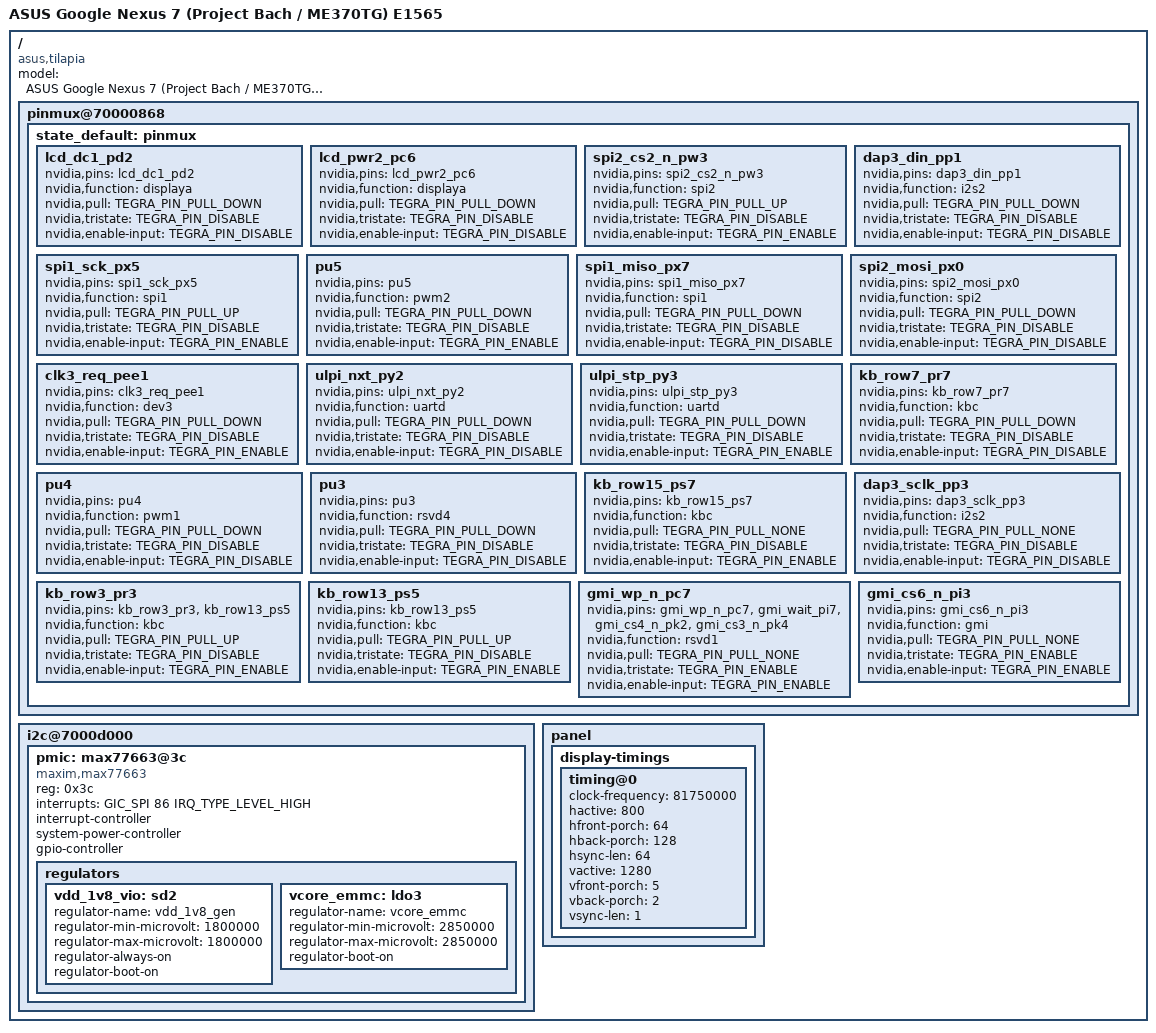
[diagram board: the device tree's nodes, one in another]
// SPDX-License-Identifier: GPL-2.0
/dts-v1/;

#include "tegra30-asus-grouper-common.dtsi"

/ {
	model = "ASUS Google Nexus 7 (Project Bach / ME370TG) E1565";
	compatible = "asus,tilapia", "nvidia,tegra30";

	pinmux@70000868 {
		state_default: pinmux {
			lcd_dc1_pd2 {
				nvidia,pins = "lcd_dc1_pd2";
				nvidia,function = "displaya";
				nvidia,pull = <TEGRA_PIN_PULL_DOWN>;
				nvidia,tristate = <TEGRA_PIN_DISABLE>;
				nvidia,enable-input = <TEGRA_PIN_DISABLE>;
			};
			lcd_pwr2_pc6 {
				nvidia,pins = "lcd_pwr2_pc6";
				nvidia,function = "displaya";
				nvidia,pull = <TEGRA_PIN_PULL_DOWN>;
				nvidia,tristate = <TEGRA_PIN_DISABLE>;
				nvidia,enable-input = <TEGRA_PIN_DISABLE>;
			};
			spi2_cs2_n_pw3 {
				nvidia,pins = "spi2_cs2_n_pw3";
				nvidia,function = "spi2";
				nvidia,pull = <TEGRA_PIN_PULL_UP>;
				nvidia,tristate = <TEGRA_PIN_DISABLE>;
				nvidia,enable-input = <TEGRA_PIN_ENABLE>;
			};
			dap3_din_pp1 {
				nvidia,pins = "dap3_din_pp1";
				nvidia,function = "i2s2";
				nvidia,pull = <TEGRA_PIN_PULL_DOWN>;
				nvidia,tristate = <TEGRA_PIN_DISABLE>;
				nvidia,enable-input = <TEGRA_PIN_DISABLE>;
			};
			spi1_sck_px5 {
				nvidia,pins = "spi1_sck_px5";
				nvidia,function = "spi1";
				nvidia,pull = <TEGRA_PIN_PULL_UP>;
				nvidia,tristate = <TEGRA_PIN_DISABLE>;
				nvidia,enable-input = <TEGRA_PIN_ENABLE>;
			};
			pu5 {
				nvidia,pins = "pu5";
				nvidia,function = "pwm2";
				nvidia,pull = <TEGRA_PIN_PULL_DOWN>;
				nvidia,tristate = <TEGRA_PIN_DISABLE>;
				nvidia,enable-input = <TEGRA_PIN_ENABLE>;
			};
			spi1_miso_px7 {
				nvidia,pins = "spi1_miso_px7";
				nvidia,function = "spi1";
				nvidia,pull = <TEGRA_PIN_PULL_DOWN>;
				nvidia,tristate = <TEGRA_PIN_DISABLE>;
				nvidia,enable-input = <TEGRA_PIN_DISABLE>;
			};
			spi2_mosi_px0 {
				nvidia,pins = "spi2_mosi_px0";
				nvidia,function = "spi2";
				nvidia,pull = <TEGRA_PIN_PULL_DOWN>;
				nvidia,tristate = <TEGRA_PIN_DISABLE>;
				nvidia,enable-input = <TEGRA_PIN_DISABLE>;
			};
			clk3_req_pee1 {
				nvidia,pins = "clk3_req_pee1";
				nvidia,function = "dev3";
				nvidia,pull = <TEGRA_PIN_PULL_DOWN>;
				nvidia,tristate = <TEGRA_PIN_DISABLE>;
				nvidia,enable-input = <TEGRA_PIN_ENABLE>;
			};
			ulpi_nxt_py2 {
				nvidia,pins = "ulpi_nxt_py2";
				nvidia,function = "uartd";
				nvidia,pull = <TEGRA_PIN_PULL_DOWN>;
				nvidia,tristate = <TEGRA_PIN_DISABLE>;
				nvidia,enable-input = <TEGRA_PIN_DISABLE>;
			};
			ulpi_stp_py3 {
				nvidia,pins = "ulpi_stp_py3";
				nvidia,function = "uartd";
				nvidia,pull = <TEGRA_PIN_PULL_DOWN>;
				nvidia,tristate = <TEGRA_PIN_DISABLE>;
				nvidia,enable-input = <TEGRA_PIN_ENABLE>;
			};
			kb_row7_pr7 {
				nvidia,pins = "kb_row7_pr7";
				nvidia,function = "kbc";
				nvidia,pull = <TEGRA_PIN_PULL_DOWN>;
				nvidia,tristate = <TEGRA_PIN_DISABLE>;
				nvidia,enable-input = <TEGRA_PIN_DISABLE>;
			};
			pu4 {
				nvidia,pins = "pu4";
				nvidia,function = "pwm1";
				nvidia,pull = <TEGRA_PIN_PULL_DOWN>;
				nvidia,tristate = <TEGRA_PIN_DISABLE>;
				nvidia,enable-input = <TEGRA_PIN_DISABLE>;
			};
			pu3 {
				nvidia,pins = "pu3";
				nvidia,function = "rsvd4";
				nvidia,pull = <TEGRA_PIN_PULL_DOWN>;
				nvidia,tristate = <TEGRA_PIN_DISABLE>;
				nvidia,enable-input = <TEGRA_PIN_DISABLE>;
			};
			kb_row15_ps7 {
				nvidia,pins = "kb_row15_ps7";
				nvidia,function = "kbc";
				nvidia,pull = <TEGRA_PIN_PULL_NONE>;
				nvidia,tristate = <TEGRA_PIN_DISABLE>;
				nvidia,enable-input = <TEGRA_PIN_ENABLE>;
			};
			dap3_sclk_pp3 {
				nvidia,pins = "dap3_sclk_pp3";
				nvidia,function = "i2s2";
				nvidia,pull = <TEGRA_PIN_PULL_NONE>;
				nvidia,tristate = <TEGRA_PIN_DISABLE>;
				nvidia,enable-input = <TEGRA_PIN_DISABLE>;
			};
			kb_row3_pr3 {
				nvidia,pins = "kb_row3_pr3",
						"kb_row13_ps5";
				nvidia,function = "kbc";
				nvidia,pull = <TEGRA_PIN_PULL_UP>;
				nvidia,tristate = <TEGRA_PIN_DISABLE>;
				nvidia,enable-input = <TEGRA_PIN_ENABLE>;
			};
			kb_row13_ps5 {
				nvidia,pins = "kb_row13_ps5";
				nvidia,function = "kbc";
				nvidia,pull = <TEGRA_PIN_PULL_UP>;
				nvidia,tristate = <TEGRA_PIN_DISABLE>;
				nvidia,enable-input = <TEGRA_PIN_ENABLE>;
			};
			gmi_wp_n_pc7 {
				nvidia,pins = "gmi_wp_n_pc7",
						"gmi_wait_pi7",
						"gmi_cs4_n_pk2",
						"gmi_cs3_n_pk4";
				nvidia,function = "rsvd1";
				nvidia,pull = <TEGRA_PIN_PULL_NONE>;
				nvidia,tristate = <TEGRA_PIN_ENABLE>;
				nvidia,enable-input = <TEGRA_PIN_ENABLE>;
			};
			gmi_cs6_n_pi3 {
				nvidia,pins = "gmi_cs6_n_pi3";
				nvidia,function = "gmi";
				nvidia,pull = <TEGRA_PIN_PULL_NONE>;
				nvidia,tristate = <TEGRA_PIN_ENABLE>;
				nvidia,enable-input = <TEGRA_PIN_ENABLE>;
			};
		};
	};

	i2c@7000d000 {
		pmic: max77663@3c {
			compatible = "maxim,max77663";
			reg = <0x3c>;

			interrupts = <GIC_SPI 86 IRQ_TYPE_LEVEL_HIGH>;
			#interrupt-cells = <2>;
			interrupt-controller;

			system-power-controller;

			#gpio-cells = <2>;
			gpio-controller;

			regulators {
				vdd_1v8_vio: sd2 {
					regulator-name = "vdd_1v8_gen";
					regulator-min-microvolt = <1800000>;
					regulator-max-microvolt = <1800000>;
					regulator-always-on;
					regulator-boot-on;
				};

				/* eMMC VDD */
				vcore_emmc: ldo3 {
					regulator-name = "vcore_emmc";
					regulator-min-microvolt = <2850000>;
					regulator-max-microvolt = <2850000>;
					regulator-boot-on;
				};
			};
		};
	};

	panel {
		display-timings {
			timing@0 {
				/* 1280x800@60Hz */
				clock-frequency = <81750000>;

				hactive = <800>;
				hfront-porch = <64>;
				hback-porch = <128>;
				hsync-len = <64>;

				vactive = <1280>;
				vfront-porch = <5>;
				vback-porch = <2>;
				vsync-len = <1>;
			};
		};
	};
};
